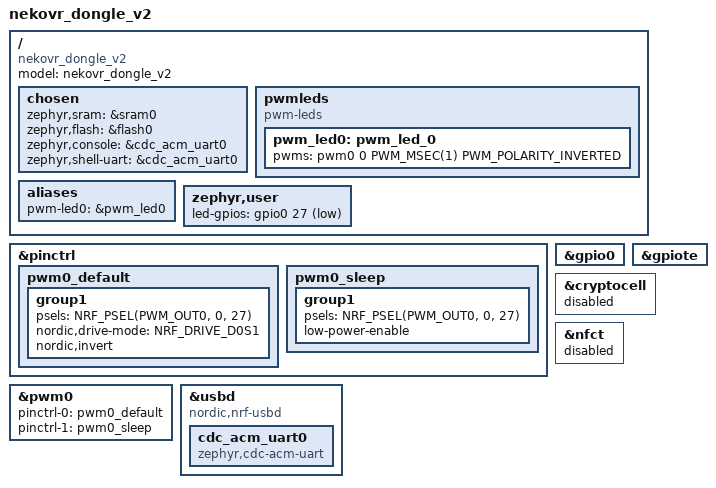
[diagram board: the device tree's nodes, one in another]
// Copyright (c) 2024 Nordic Semiconductor ASA
// SPDX-License-Identifier: Apache-2.0

/dts-v1/;
#include <nordic/nrf52840_qiaa.dtsi>

//move to dtsi?
&pinctrl {
	pwm0_default: pwm0_default {
		group1 {
			psels = <NRF_PSEL(PWM_OUT0, 0, 27)>;
			nordic,drive-mode = <NRF_DRIVE_D0S1>;
			nordic,invert;
		};
	};

	pwm0_sleep: pwm0_sleep {
		group1 {
			psels = <NRF_PSEL(PWM_OUT0, 0, 27)>;
			low-power-enable;
		};
	};
};
//end

/ {
	model = "nekovr_dongle_v2";
	compatible = "nekovr_dongle_v2";

	chosen {
		zephyr,sram = &sram0;
		zephyr,flash = &flash0;
		zephyr,console = &cdc_acm_uart0;
		zephyr,shell-uart = &cdc_acm_uart0;
	};

	pwmleds {
		compatible = "pwm-leds";
		pwm_led0: pwm_led_0 {
			pwms = <&pwm0 0 PWM_MSEC(1) PWM_POLARITY_INVERTED>;
		};
	};

	aliases {
		pwm-led0 = &pwm_led0;
	};

	zephyr,user {
		led-gpios = <&gpio0 27 (GPIO_ACTIVE_LOW | GPIO_OPEN_DRAIN)>;
		// red 1.09, green 1.15, blue 0.07
	};
};

&gpio0 {
	status = "okay";
};

&gpiote {
	status = "okay";
};

&pwm0 {
	status = "okay";
	pinctrl-0 = <&pwm0_default>;
	pinctrl-1 = <&pwm0_sleep>;
	pinctrl-names = "default", "sleep";
};

zephyr_udc0: &usbd {
	compatible = "nordic,nrf-usbd";
	status = "okay";
	cdc_acm_uart0: cdc_acm_uart0 {
		compatible = "zephyr,cdc-acm-uart";
	};
};

&cryptocell {
	status = "disabled";
};

&nfct {
	status = "disabled";
};
